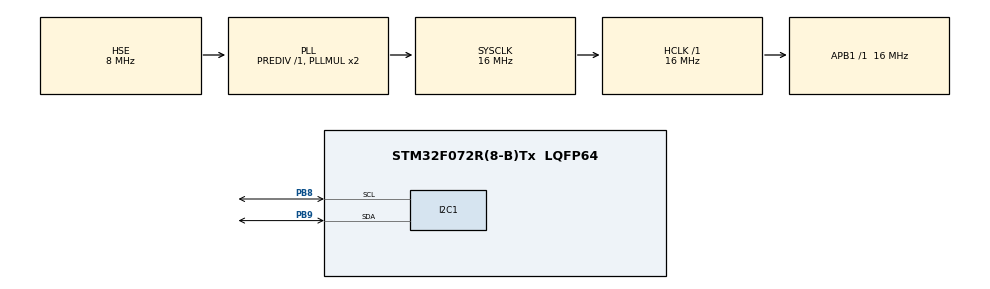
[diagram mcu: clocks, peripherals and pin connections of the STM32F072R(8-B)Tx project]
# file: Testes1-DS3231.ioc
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I2C1.Timing=0x00201D2B
Mcu.Family=STM32F0
Mcu.Name=STM32F072R(8-B)Tx
Mcu.Package=LQFP64
NVIC.TIM1_BRK_UP_TRG_COM_IRQn=true\:3\:0\:false\:false\:true\:false\:true\:true
NVIC.TimeBase=TIM1_BRK_UP_TRG_COM_IRQn
NVIC.TimeBaseIP=TIM1
PA13.Mode=Serial_Wire
PA13.Signal=SYS_SWDIO
PA14.Mode=Serial_Wire
PA14.Signal=SYS_SWCLK
PB8.Mode=I2C
PB8.Signal=I2C1_SCL
PB9.Mode=I2C
PB9.Signal=I2C1_SDA
PF0-OSC_IN.Mode=HSE-External-Oscillator
PF0-OSC_IN.Signal=RCC_OSC_IN
PF1-OSC_OUT.Mode=HSE-External-Oscillator
PF1-OSC_OUT.Signal=RCC_OSC_OUT
ProjectManager.HeapSize=0x200
ProjectManager.StackSize=0x400
ProjectManager.TargetToolchain=STM32CubeIDE
RCC.AHBFreq_Value=16000000
RCC.APB1Freq_Value=16000000
RCC.APB1TimFreq_Value=16000000
RCC.HCLKFreq_Value=16000000
RCC.PLLSourceVirtual=RCC_PLLSOURCE_HSE
RCC.SYSCLKFreq_VALUE=16000000
RCC.SYSCLKSource=RCC_SYSCLKSOURCE_PLLCLK
VP_SYS_VS_tim1.Mode=TIM1
board=custom

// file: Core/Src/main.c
/* USER CODE BEGIN Header */
/**
  ******************************************************************************
  * @file           : main.c
  * @brief          : Main program body
  ******************************************************************************
  * @attention
  *
  * Copyright (c) 2024 STMicroelectronics.
  * All rights reserved.
  *
  * This software is licensed under terms that can be found in the LICENSE file
  * in the root directory of this software component.
  * If no LICENSE file comes with this software, it is provided AS-IS.
  *
  ******************************************************************************
  */
/* USER CODE END Header */
#include "main.h"

/* USER CODE BEGIN Includes */
#include "DS3231.h"

/* USER CODE END Includes */

I2C_HandleTypeDef hi2c1;

/* USER CODE BEGIN PV */
I2C_HandleTypeDef hi2c1;

uint8_t  sec,min,hour,day,date,month,year;

/* USER CODE END PV */

void SystemClock_Config(void);
static void MX_GPIO_Init(void);
static void MX_I2C1_Init(void);

int main(void)
{

  /* MCU Configuration--------------------------------------------------------*/

  /* Reset of all peripherals, Initializes the Flash interface and the Systick. */
  HAL_Init();

  /* Configure the system clock */
  SystemClock_Config();

  /* Initialize all configured peripherals */
  MX_GPIO_Init();
  MX_I2C1_Init();
  /* USER CODE BEGIN 2 */
  Set_Time(20, 58, 9, 3, 04, 01, 24);//fourth parameter is not important(100)
  // setar com 20s de antecedencia
  //IDEIA: alterar a data inicial via telecomando (o mesmo que inicia o satelite)

  /* USER CODE END 2 */

  /* Infinite loop */
  /* USER CODE BEGIN WHILE */
  while (1)
  {
	  Get_Time(&sec,&min,&hour,&day,&date,&month,&year);
	  HAL_Delay(1000);
    /* USER CODE END WHILE */

  }
}

void SystemClock_Config(void)
{
  RCC_OscInitTypeDef RCC_OscInitStruct = {0};
  RCC_ClkInitTypeDef RCC_ClkInitStruct = {0};
  RCC_PeriphCLKInitTypeDef PeriphClkInit = {0};

  /** Initializes the RCC Oscillators according to the specified parameters
  * in the RCC_OscInitTypeDef structure.
  */
  RCC_OscInitStruct.OscillatorType = RCC_OSCILLATORTYPE_HSI|RCC_OSCILLATORTYPE_HSE;
  RCC_OscInitStruct.HSEState = RCC_HSE_ON;
  RCC_OscInitStruct.HSIState = RCC_HSI_ON;
  RCC_OscInitStruct.HSICalibrationValue = RCC_HSICALIBRATION_DEFAULT;
  RCC_OscInitStruct.PLL.PLLState = RCC_PLL_ON;
  RCC_OscInitStruct.PLL.PLLSource = RCC_PLLSOURCE_HSE;
  RCC_OscInitStruct.PLL.PLLMUL = RCC_PLL_MUL2;
  RCC_OscInitStruct.PLL.PREDIV = RCC_PREDIV_DIV1;
  if (HAL_RCC_OscConfig(&RCC_OscInitStruct) != HAL_OK)
  {
    Error_Handler();
  }

  /** Initializes the CPU, AHB and APB buses clocks
  */
  RCC_ClkInitStruct.ClockType = RCC_CLOCKTYPE_HCLK|RCC_CLOCKTYPE_SYSCLK
                              |RCC_CLOCKTYPE_PCLK1;
  RCC_ClkInitStruct.SYSCLKSource = RCC_SYSCLKSOURCE_PLLCLK;
  RCC_ClkInitStruct.AHBCLKDivider = RCC_SYSCLK_DIV1;
  RCC_ClkInitStruct.APB1CLKDivider = RCC_HCLK_DIV1;

  if (HAL_RCC_ClockConfig(&RCC_ClkInitStruct, FLASH_LATENCY_0) != HAL_OK)
  {
    Error_Handler();
  }
  PeriphClkInit.PeriphClockSelection = RCC_PERIPHCLK_I2C1;
  PeriphClkInit.I2c1ClockSelection = RCC_I2C1CLKSOURCE_HSI;
  if (HAL_RCCEx_PeriphCLKConfig(&PeriphClkInit) != HAL_OK)
  {
    Error_Handler();
  }
}

static void MX_I2C1_Init(void)
{

  hi2c1.Instance = I2C1;
  hi2c1.Init.Timing = 0x00201D2B;
  hi2c1.Init.OwnAddress1 = 0;
  hi2c1.Init.AddressingMode = I2C_ADDRESSINGMODE_7BIT;
  hi2c1.Init.DualAddressMode = I2C_DUALADDRESS_DISABLE;
  hi2c1.Init.OwnAddress2 = 0;
  hi2c1.Init.OwnAddress2Masks = I2C_OA2_NOMASK;
  hi2c1.Init.GeneralCallMode = I2C_GENERALCALL_DISABLE;
  hi2c1.Init.NoStretchMode = I2C_NOSTRETCH_DISABLE;
  if (HAL_I2C_Init(&hi2c1) != HAL_OK)
  {
    Error_Handler();
  }

  /** Configure Analogue filter
  */
  if (HAL_I2CEx_ConfigAnalogFilter(&hi2c1, I2C_ANALOGFILTER_ENABLE) != HAL_OK)
  {
    Error_Handler();
  }

  /** Configure Digital filter
  */
  if (HAL_I2CEx_ConfigDigitalFilter(&hi2c1, 0) != HAL_OK)
  {
    Error_Handler();
  }

}

static void MX_GPIO_Init(void)
{

  /* GPIO Ports Clock Enable */
  __HAL_RCC_GPIOF_CLK_ENABLE();
  __HAL_RCC_GPIOA_CLK_ENABLE();
  __HAL_RCC_GPIOB_CLK_ENABLE();

}

void HAL_TIM_PeriodElapsedCallback(TIM_HandleTypeDef *htim)
{
  if (htim->Instance == TIM1) {
    HAL_IncTick();
  }
}

void Error_Handler(void)
{
  __disable_irq();
  while (1)
  {
  }
}
